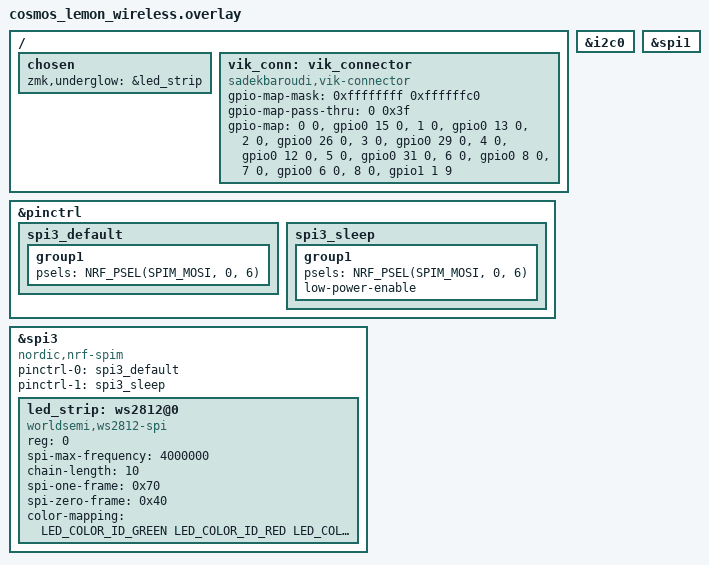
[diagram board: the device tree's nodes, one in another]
#include <dt-bindings/led/led.h>

&pinctrl {
    spi3_default: spi3_default {
        group1 {
            psels = <NRF_PSEL(SPIM_MOSI, 0, 6)>;
        };
    };

    spi3_sleep: spi3_sleep {
        group1 {
            psels = <NRF_PSEL(SPIM_MOSI, 0, 6)>;
            low-power-enable;
        };
    };
};

&spi3 {
    compatible = "nordic,nrf-spim";
    status = "okay";

    pinctrl-0 = <&spi3_default>;
    pinctrl-1 = <&spi3_sleep>;
    pinctrl-names = "default", "sleep";

    led_strip: ws2812@0 {
        compatible = "worldsemi,ws2812-spi";

        /* SPI */
        reg = <0>; /* ignored, but necessary for SPI bindings */
        spi-max-frequency = <4000000>;

        /* WS2812 */
        chain-length = <10>; /* arbitrary; change at will */
        spi-one-frame = <0x70>;
        spi-zero-frame = <0x40>;

        color-mapping = <LED_COLOR_ID_GREEN LED_COLOR_ID_RED LED_COLOR_ID_BLUE>;
    };
};

/ {
    chosen {
        zmk,underglow = &led_strip;
    };

    vik_conn: vik_connector {
		    compatible = "sadekbaroudi,vik-connector";
        #gpio-cells = <2>;
        gpio-map-mask = <0xffffffff 0xffffffc0>;
        gpio-map-pass-thru = <0 0x3f>;
        gpio-map
          = <0 0 &gpio0  15 0>   /* vik SDA */
          , <1 0 &gpio0  13 0>   /* vik SCL */
          , <2 0 &gpio0  26 0>   /* vik RGB Data */
          , <3 0 &gpio0  29 0>   /* vik AD_1 */
          , <4 0 &gpio0  12 0>   /* vik MOSI */
          , <5 0 &gpio0  31 0>   /* vik AD_2 */
          , <6 0 &gpio0  8 0>    /* vik CS */
          , <7 0 &gpio0  6 0>    /* vik MISO */
          , <8 0 &gpio1  1 9>    /* vik SCLK */
          ;
    };
};

vik_i2c: &i2c0 {};
vik_spi: &spi1 {};
